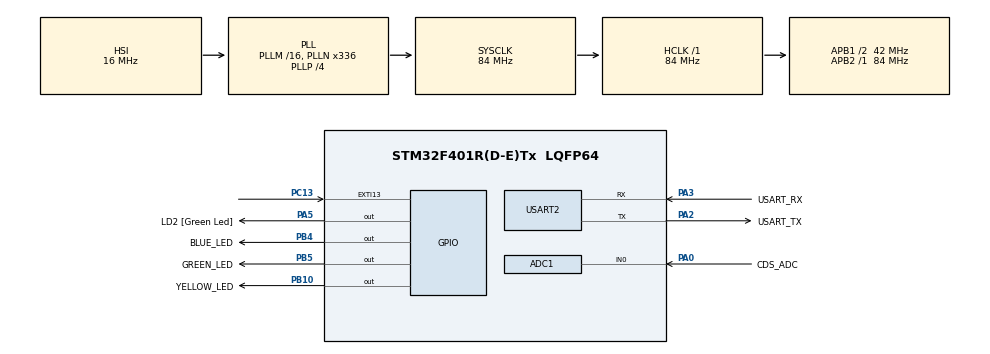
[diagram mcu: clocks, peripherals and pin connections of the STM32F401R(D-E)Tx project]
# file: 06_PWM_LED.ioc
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ADC1.Channel-0\#ChannelRegularConversion=ADC_CHANNEL_0
ADC1.ClockPrescaler=ADC_CLOCK_SYNC_PCLK_DIV4
ADC1.NbrOfConversionFlag=1
ADC1.Rank-0\#ChannelRegularConversion=1
ADC1.SamplingTime-0\#ChannelRegularConversion=ADC_SAMPLETIME_84CYCLES
Dma.Request0=USART2_RX
Dma.Request1=USART2_TX
Dma.USART2_RX.0.Channel=DMA_CHANNEL_4
Dma.USART2_RX.0.Direction=DMA_PERIPH_TO_MEMORY
Dma.USART2_RX.0.FIFOMode=DMA_FIFOMODE_DISABLE
Dma.USART2_RX.0.Instance=DMA1_Stream5
Dma.USART2_RX.0.MemDataAlignment=DMA_MDATAALIGN_BYTE
Dma.USART2_RX.0.MemInc=DMA_MINC_ENABLE
Dma.USART2_RX.0.Mode=DMA_NORMAL
Dma.USART2_RX.0.PeriphDataAlignment=DMA_PDATAALIGN_BYTE
Dma.USART2_RX.0.PeriphInc=DMA_PINC_DISABLE
Dma.USART2_RX.0.Priority=DMA_PRIORITY_LOW
Dma.USART2_TX.1.Channel=DMA_CHANNEL_4
Dma.USART2_TX.1.Direction=DMA_MEMORY_TO_PERIPH
Dma.USART2_TX.1.FIFOMode=DMA_FIFOMODE_DISABLE
Dma.USART2_TX.1.Instance=DMA1_Stream6
Dma.USART2_TX.1.MemDataAlignment=DMA_MDATAALIGN_BYTE
Dma.USART2_TX.1.MemInc=DMA_MINC_ENABLE
Dma.USART2_TX.1.Mode=DMA_NORMAL
Dma.USART2_TX.1.PeriphDataAlignment=DMA_PDATAALIGN_BYTE
Dma.USART2_TX.1.PeriphInc=DMA_PINC_DISABLE
Dma.USART2_TX.1.Priority=DMA_PRIORITY_LOW
Mcu.Family=STM32F4
Mcu.Name=STM32F401R(D-E)Tx
Mcu.Package=LQFP64
NVIC.DMA1_Stream5_IRQn=true\:0\:0\:false\:false\:true\:false\:true\:true
NVIC.DMA1_Stream6_IRQn=true\:0\:0\:false\:false\:true\:false\:true\:true
NVIC.PriorityGroup=NVIC_PRIORITYGROUP_4
NVIC.TIM2_IRQn=true\:0\:0\:false\:false\:true\:true\:true\:true
NVIC.USART2_IRQn=true\:0\:0\:false\:false\:true\:true\:true\:true
PA0-WKUP.GPIO_Label=CDS_ADC
PA0-WKUP.Mode=IN0
PA0-WKUP.Signal=ADC1_IN0
PA13.GPIO_Label=TMS
PA13.Mode=Trace_Asynchronous_SW
PA13.Signal=SYS_JTMS-SWDIO
PA14.GPIO_Label=TCK
PA14.Mode=Trace_Asynchronous_SW
PA14.Signal=SYS_JTCK-SWCLK
PA2.GPIO_Label=USART_TX
PA2.GPIO_Mode=GPIO_MODE_AF_PP
PA2.GPIO_PuPd=GPIO_NOPULL
PA2.GPIO_Speed=GPIO_SPEED_FREQ_LOW
PA2.Mode=Asynchronous
PA2.Signal=USART2_TX
PA3.GPIO_Label=USART_RX
PA3.GPIO_Mode=GPIO_MODE_AF_PP
PA3.GPIO_PuPd=GPIO_NOPULL
PA3.GPIO_Speed=GPIO_SPEED_FREQ_LOW
PA3.Mode=Asynchronous
PA3.Signal=USART2_RX
PA5.GPIO_Label=LD2 [Green Led]
PA5.GPIO_Mode=GPIO_MODE_OUTPUT_PP
PA5.GPIO_PuPd=GPIO_NOPULL
PA5.GPIO_Speed=GPIO_SPEED_FREQ_LOW
PA5.Signal=GPIO_Output
PA8.GPIO_Alternate=GPIO_AF1_TIM1
PA8.GPIO_Label=PWM_RED_LED
PA8.GPIO_Mode=GPIO_MODE_AF_PP
PA8.GPIO_PuPd=GPIO_NOPULL
PA8.GPIO_Speed=GPIO_SPEED_FREQ_LOW
PA8.Signal=S_TIM1_CH1
PB10.GPIO_Label=YELLOW_LED
PB10.Signal=GPIO_Output
PB3.GPIO_Label=SWO
PB3.Mode=Trace_Asynchronous_SW
PB3.Signal=SYS_JTDO-SWO
PB4.GPIO_Label=BLUE_LED
PB4.Signal=GPIO_Output
PB5.GPIO_Label=GREEN_LED
PB5.Signal=GPIO_Output
PC13-ANTI_TAMP.Signal=GPXTI13
PC14-OSC32_IN.Mode=LSE-External-Oscillator
PC14-OSC32_IN.Signal=RCC_OSC32_IN
PC15-OSC32_OUT.Mode=LSE-External-Oscillator
PC15-OSC32_OUT.Signal=RCC_OSC32_OUT
PH0\ -\ OSC_IN.Mode=HSE-External-Clock-Source
PH0\ -\ OSC_IN.Signal=RCC_OSC_IN
PH1\ -\ OSC_OUT.Mode=HSE-External-Clock-Source
PH1\ -\ OSC_OUT.Signal=RCC_OSC_OUT
ProjectManager.HeapSize=0x200
ProjectManager.StackSize=0x400
ProjectManager.TargetToolchain=CMake
RCC.48MHZClocksFreq_Value=48000000
RCC.AHBFreq_Value=84000000
RCC.APB1CLKDivider=RCC_HCLK_DIV2
RCC.APB1Freq_Value=42000000
RCC.APB1TimFreq_Value=84000000
RCC.APB2Freq_Value=84000000
RCC.APB2TimFreq_Value=84000000
RCC.CortexFreq_Value=84000000
RCC.HCLKFreq_Value=84000000
RCC.HSE_VALUE=8000000
RCC.HSI_VALUE=16000000
RCC.PLLN=336
RCC.PLLP=RCC_PLLP_DIV4
RCC.PLLQ=7
RCC.SYSCLKFreq_VALUE=84000000
RCC.SYSCLKSource=RCC_SYSCLKSOURCE_PLLCLK
RCC.VCOOutputFreq_Value=336000000
USART2.DMAParams=USART2_RX,USART2_TX
USART2.VirtualMode=VM_ASYNC
TIM1.Channel-PWM\ Generation1=TIM_CHANNEL_1
TIM1.Period=999
TIM1.Prescaler=83
TIM1.Pulse-PWM\ Generation1=0
TIM2.Period=4999
TIM2.Prescaler=8399
board=NUCLEO-F401RE

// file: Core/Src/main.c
/* USER CODE BEGIN Header */
/**
  ******************************************************************************
  * @file           : main.c
  * @brief          : Main program body
  ******************************************************************************
  * @attention
  *
  * Copyright (c) 2026 STMicroelectronics.
  * All rights reserved.
  *
  * This software is licensed under terms that can be found in the LICENSE file
  * in the root directory of this software component.
  * If no LICENSE file comes with this software, it is provided AS-IS.
  *
  ******************************************************************************
  */
/* USER CODE END Header */
#include "main.h"

/* USER CODE BEGIN Includes */

#include <stdio.h>
#include <string.h>

/* USER CODE END Includes */

/* USER CODE BEGIN PTD */

typedef enum
{
  LED_STATE_IDLE,
  LED_STATE_RUNNING,
  LED_STATE_WARNING,
  LED_STATE_ERROR,
  LED_STATE_COUNT
} LED_State;

/* USER CODE END PTD */

/* USER CODE BEGIN PD */

#define BUTTON_DEBOUNCE_MS 50U
#define UART_RX_BUFFER_SIZE 32U
#define PWM_PERIOD 999U
#define UART_TX_BUFFER_SIZE 128U
#define CDS_BRIGHT_THRESHOLD 1200U
#define CDS_NORMAL_THRESHOLD 2100U
#define CDS_DIM_THRESHOLD 3000U

/* USER CODE END PD */

ADC_HandleTypeDef hadc1;
TIM_HandleTypeDef htim1;
TIM_HandleTypeDef htim2;

/* USART2 설정과 상태를 HAL 드라이버에 전달하는 핸들 */
UART_HandleTypeDef huart2;
DMA_HandleTypeDef hdma_usart2_rx;
DMA_HandleTypeDef hdma_usart2_tx;

/* USER CODE BEGIN PV */

static LED_State currentState = LED_STATE_IDLE;
static uint8_t uartDmaRxBuffer[UART_RX_BUFFER_SIZE];
static char uartRxBuffer[UART_RX_BUFFER_SIZE];
static volatile uint8_t uartRxIndex = 0U;
static volatile uint8_t uartCommandReady = 0U;
static volatile uint8_t uartRxOverflow = 0U;
static uint8_t uartDmaTxBuffer[UART_TX_BUFFER_SIZE];
static volatile uint8_t uartDmaTxComplete = 1U;
static volatile uint8_t timerSampleRequested = 0U;

/* USER CODE END PV */

void SystemClock_Config(void);
void HAL_TIM_MspPostInit(TIM_HandleTypeDef *htim);
static void MX_ADC1_Init(void);
static void MX_TIM1_Init(void);
static void MX_TIM2_Init(void);
static void MX_GPIO_Init(void);
static void MX_DMA_Init(void);
static void MX_USART2_UART_Init(void);
/* USER CODE BEGIN PFP */

static void LED_AllOff(void);
static void LED_On(GPIO_TypeDef *GPIOx, uint16_t GPIO_Pin);
static void LED_ShowState(LED_State state);
static void UART_PrintState(LED_State state);
static void UART_HandleCommand(const char *command);
static void UART_StartDmaReceive(void);
static void UART_StoreReceivedData(const uint8_t *data, uint16_t size);
static HAL_StatusTypeDef ADC_ReadCdS(uint32_t *rawValue);
static void CdS_ProcessSample(void);
static void PWM_SetDutyFromCdS(uint32_t rawValue);
static LED_State CdS_GetBrightnessState(uint32_t rawValue);
static const char *CdS_GetBrightnessName(LED_State state);

/* USER CODE END PFP */

/* USER CODE BEGIN 0 */

int _write(int file, char *ptr, int len)
{
  int sent = 0;

  (void)file;

  while (sent < len)
  {
    uint16_t chunkSize = (uint16_t)(len - sent);

    if (chunkSize > UART_TX_BUFFER_SIZE)
    {
      chunkSize = UART_TX_BUFFER_SIZE;
    }

    memcpy(uartDmaTxBuffer, &ptr[sent], chunkSize);
    uartDmaTxComplete = 0U;

    if (HAL_UART_Transmit_DMA(&huart2, uartDmaTxBuffer, chunkSize) != HAL_OK)
    {
      return -1;
    }

    while (uartDmaTxComplete == 0U)
    {
      __WFI();
    }

    sent += chunkSize;
  }

  return len;
}

/* USER CODE END 0 */

int main(void)
{

  /* USER CODE BEGIN 1 */

  GPIO_PinState lastButtonReading = GPIO_PIN_RESET;
  GPIO_PinState stableButtonState = GPIO_PIN_RESET;
  uint32_t lastDebounceTime = 0U;

  /* USER CODE END 1 */

  /* MCU Configuration--------------------------------------------------------*/

  /* HAL 라이브러리, Flash 인터페이스, 1 ms 주기의 SysTick 타이머를 초기화한다. */
  HAL_Init();

  /* 내부 HSI 오실레이터와 PLL을 이용해 시스템 클럭을 84 MHz로 설정한다. */
  SystemClock_Config();

  MX_ADC1_Init();
  MX_TIM1_Init();
  MX_TIM2_Init();

  /* LED와 사용자 버튼이 연결된 GPIO를 초기화한다. */
  MX_GPIO_Init();

  MX_DMA_Init();

  /* ST-LINK 가상 COM 포트에 연결된 USART2를 115200 bps로 초기화한다. */
  MX_USART2_UART_Init();
  /* USER CODE BEGIN 2 */

  LED_ShowState(currentState);

  printf("Hello STM32!\r\n");
  UART_PrintState(currentState);

  UART_StartDmaReceive();

  if (HAL_TIM_PWM_Start(&htim1, TIM_CHANNEL_1) != HAL_OK)
  {
    Error_Handler();
  }

  if (HAL_TIM_Base_Start_IT(&htim2) != HAL_OK)
  {
    Error_Handler();
  }

  /* USER CODE END 2 */

  /* 초기화가 끝난 뒤 프로그램이 계속 실행되는 메인 반복 구간 */
  /* USER CODE BEGIN WHILE */
  while (1)
  {
    if (timerSampleRequested != 0U)
    {
      timerSampleRequested = 0U;
      CdS_ProcessSample();
    }

    GPIO_PinState buttonReading = HAL_GPIO_ReadPin(USER_BUTTON_GPIO_Port, USER_BUTTON_Pin);

    if (buttonReading != lastButtonReading)
    {
      lastDebounceTime = HAL_GetTick();
    }

    if ((HAL_GetTick() - lastDebounceTime) >= BUTTON_DEBOUNCE_MS)
    {
      if (buttonReading != stableButtonState)
      {
        stableButtonState = buttonReading;

        if (stableButtonState == GPIO_PIN_SET)
        {
          currentState = (LED_State)((currentState + 1) % LED_STATE_COUNT);
          LED_ShowState(currentState);
          UART_PrintState(currentState);
        }
      }
    }

    lastButtonReading = buttonReading;

    if (uartCommandReady != 0U)
    {
      if (uartRxOverflow != 0U)
      {
        printf("Command too long\r\n");
      }
      else
      {
        UART_HandleCommand(uartRxBuffer);
      }

      uartRxIndex = 0U;
      uartRxOverflow = 0U;
      uartCommandReady = 0U;
    }
    /* USER CODE END WHILE */

  }
}

void SystemClock_Config(void)
{
  /* 오실레이터와 버스 클럭 설정 구조체를 0으로 초기화한다. */
  RCC_OscInitTypeDef RCC_OscInitStruct = {0};
  RCC_ClkInitTypeDef RCC_ClkInitStruct = {0};

  /** 전원 제어 장치의 클럭을 활성화하고 84 MHz 동작에 맞는 전압 스케일을 선택한다.
  */
  __HAL_RCC_PWR_CLK_ENABLE();
  __HAL_PWR_VOLTAGESCALING_CONFIG(PWR_REGULATOR_VOLTAGE_SCALE2);

  /** 16 MHz 내부 HSI를 PLL 입력으로 사용해 84 MHz 시스템 클럭을 만든다.
  * in the RCC_OscInitTypeDef structure.
  */
  RCC_OscInitStruct.OscillatorType = RCC_OSCILLATORTYPE_HSI;
  RCC_OscInitStruct.HSIState = RCC_HSI_ON;
  RCC_OscInitStruct.HSICalibrationValue = RCC_HSICALIBRATION_DEFAULT;
  RCC_OscInitStruct.PLL.PLLState = RCC_PLL_ON;
  RCC_OscInitStruct.PLL.PLLSource = RCC_PLLSOURCE_HSI;
  RCC_OscInitStruct.PLL.PLLM = 16;
  RCC_OscInitStruct.PLL.PLLN = 336;
  RCC_OscInitStruct.PLL.PLLP = RCC_PLLP_DIV4;
  RCC_OscInitStruct.PLL.PLLQ = 7;
  /* 오실레이터 설정에 실패하면 안전하게 오류 처리 루틴으로 이동한다. */
  if (HAL_RCC_OscConfig(&RCC_OscInitStruct) != HAL_OK)
  {
    Error_Handler();
  }

  /** SYSCLK와 AHB는 84 MHz, APB1은 42 MHz, APB2는 84 MHz로 설정한다.
  */
  RCC_ClkInitStruct.ClockType = RCC_CLOCKTYPE_HCLK|RCC_CLOCKTYPE_SYSCLK
                              |RCC_CLOCKTYPE_PCLK1|RCC_CLOCKTYPE_PCLK2;
  RCC_ClkInitStruct.SYSCLKSource = RCC_SYSCLKSOURCE_PLLCLK;
  RCC_ClkInitStruct.AHBCLKDivider = RCC_SYSCLK_DIV1;
  RCC_ClkInitStruct.APB1CLKDivider = RCC_HCLK_DIV2;
  RCC_ClkInitStruct.APB2CLKDivider = RCC_HCLK_DIV1;

  if (HAL_RCC_ClockConfig(&RCC_ClkInitStruct, FLASH_LATENCY_2) != HAL_OK)
  {
    Error_Handler();
  }
}

static void MX_ADC1_Init(void)
{
  ADC_ChannelConfTypeDef channelConfig = {0};

  hadc1.Instance = ADC1;
  hadc1.Init.ClockPrescaler = ADC_CLOCK_SYNC_PCLK_DIV4;
  hadc1.Init.Resolution = ADC_RESOLUTION_12B;
  hadc1.Init.ScanConvMode = DISABLE;
  hadc1.Init.ContinuousConvMode = DISABLE;
  hadc1.Init.DiscontinuousConvMode = DISABLE;
  hadc1.Init.ExternalTrigConvEdge = ADC_EXTERNALTRIGCONVEDGE_NONE;
  hadc1.Init.ExternalTrigConv = ADC_SOFTWARE_START;
  hadc1.Init.DataAlign = ADC_DATAALIGN_RIGHT;
  hadc1.Init.NbrOfConversion = 1;
  hadc1.Init.DMAContinuousRequests = DISABLE;
  hadc1.Init.EOCSelection = ADC_EOC_SINGLE_CONV;

  if (HAL_ADC_Init(&hadc1) != HAL_OK)
  {
    Error_Handler();
  }

  channelConfig.Channel = ADC_CHANNEL_0;
  channelConfig.Rank = 1;
  channelConfig.SamplingTime = ADC_SAMPLETIME_84CYCLES;

  if (HAL_ADC_ConfigChannel(&hadc1, &channelConfig) != HAL_OK)
  {
    Error_Handler();
  }
}

static void MX_TIM2_Init(void)
{
  htim2.Instance = TIM2;
  htim2.Init.Prescaler = 8399;
  htim2.Init.CounterMode = TIM_COUNTERMODE_UP;
  htim2.Init.Period = 4999;
  htim2.Init.ClockDivision = TIM_CLOCKDIVISION_DIV1;
  htim2.Init.AutoReloadPreload = TIM_AUTORELOAD_PRELOAD_DISABLE;

  if (HAL_TIM_Base_Init(&htim2) != HAL_OK)
  {
    Error_Handler();
  }
}

static void MX_TIM1_Init(void)
{
  TIM_OC_InitTypeDef channelConfig = {0};

  htim1.Instance = TIM1;
  htim1.Init.Prescaler = 83;
  htim1.Init.CounterMode = TIM_COUNTERMODE_UP;
  htim1.Init.Period = PWM_PERIOD;
  htim1.Init.ClockDivision = TIM_CLOCKDIVISION_DIV1;
  htim1.Init.RepetitionCounter = 0;
  htim1.Init.AutoReloadPreload = TIM_AUTORELOAD_PRELOAD_DISABLE;

  if (HAL_TIM_PWM_Init(&htim1) != HAL_OK)
  {
    Error_Handler();
  }

  channelConfig.OCMode = TIM_OCMODE_PWM1;
  channelConfig.Pulse = 0;
  channelConfig.OCPolarity = TIM_OCPOLARITY_HIGH;
  channelConfig.OCFastMode = TIM_OCFAST_DISABLE;

  if (HAL_TIM_PWM_ConfigChannel(&htim1, &channelConfig, TIM_CHANNEL_1) != HAL_OK)
  {
    Error_Handler();
  }

  HAL_TIM_MspPostInit(&htim1);
}

static void MX_DMA_Init(void)
{
  __HAL_RCC_DMA1_CLK_ENABLE();

  HAL_NVIC_SetPriority(DMA1_Stream5_IRQn, 0, 0);
  HAL_NVIC_EnableIRQ(DMA1_Stream5_IRQn);

  HAL_NVIC_SetPriority(DMA1_Stream6_IRQn, 0, 0);
  HAL_NVIC_EnableIRQ(DMA1_Stream6_IRQn);
}

static void MX_USART2_UART_Init(void)
{

  /* USART2: 115200 bps, 데이터 8비트, 패리티 없음, 정지 비트 1개(8-N-1) */
  huart2.Instance = USART2;
  huart2.Init.BaudRate = 115200;
  huart2.Init.WordLength = UART_WORDLENGTH_8B;
  huart2.Init.StopBits = UART_STOPBITS_1;
  huart2.Init.Parity = UART_PARITY_NONE;
  huart2.Init.Mode = UART_MODE_TX_RX;
  huart2.Init.HwFlowCtl = UART_HWCONTROL_NONE;
  huart2.Init.OverSampling = UART_OVERSAMPLING_16;
  if (HAL_UART_Init(&huart2) != HAL_OK)
  {
    Error_Handler();
  }

}

static void MX_GPIO_Init(void)
{
  /* 한 개 이상의 GPIO 핀에 공통으로 적용할 설정 구조체 */
  GPIO_InitTypeDef GPIO_InitStruct = {0};

  /* GPIO 레지스터에 접근할 수 있도록 사용하는 포트의 클럭을 활성화한다. */
  __HAL_RCC_GPIOC_CLK_ENABLE();
  __HAL_RCC_GPIOH_CLK_ENABLE();
  __HAL_RCC_GPIOA_CLK_ENABLE();
  __HAL_RCC_GPIOB_CLK_ENABLE();

  /* 초기화 중 LED가 의도치 않게 켜지지 않도록 모든 LED 출력을 LOW로 만든다. */
  HAL_GPIO_WritePin(GPIOA, LD2_Pin, GPIO_PIN_RESET);

  /*Configure GPIO pin Output Level */
  HAL_GPIO_WritePin(GPIOB, YELLOW_LED_Pin|BLUE_LED_Pin|GREEN_LED_Pin, GPIO_PIN_RESET);

  /* PC13 사용자 버튼을 폴링 입력으로 사용한다. */
  GPIO_InitStruct.Pin = USER_BUTTON_Pin;
  GPIO_InitStruct.Mode = GPIO_MODE_INPUT;
  GPIO_InitStruct.Pull = GPIO_NOPULL;
  HAL_GPIO_Init(USER_BUTTON_GPIO_Port, &GPIO_InitStruct);

  /* PA5(LD2): 푸시풀 출력, 내부 풀업/풀다운 없음 */
  GPIO_InitStruct.Pin = LD2_Pin;
  GPIO_InitStruct.Mode = GPIO_MODE_OUTPUT_PP;
  GPIO_InitStruct.Pull = GPIO_NOPULL;
  GPIO_InitStruct.Speed = GPIO_SPEED_FREQ_LOW;
  HAL_GPIO_Init(GPIOA, &GPIO_InitStruct);

  /* PB10(노랑), PB4(파랑), PB5(초록 LED): 푸시풀 출력 */
  GPIO_InitStruct.Pin = YELLOW_LED_Pin|BLUE_LED_Pin|GREEN_LED_Pin;
  GPIO_InitStruct.Mode = GPIO_MODE_OUTPUT_PP;
  GPIO_InitStruct.Pull = GPIO_NOPULL;
  GPIO_InitStruct.Speed = GPIO_SPEED_FREQ_LOW;
  HAL_GPIO_Init(GPIOB, &GPIO_InitStruct);

}

/* USER CODE BEGIN 4 */

static HAL_StatusTypeDef ADC_ReadCdS(uint32_t *rawValue)
{
  HAL_StatusTypeDef status;

  status = HAL_ADC_Start(&hadc1);
  if (status != HAL_OK)
  {
    return status;
  }

  status = HAL_ADC_PollForConversion(&hadc1, 10U);
  if (status == HAL_OK)
  {
    *rawValue = HAL_ADC_GetValue(&hadc1);
  }

  if (HAL_ADC_Stop(&hadc1) != HAL_OK && status == HAL_OK)
  {
    status = HAL_ERROR;
  }

  return status;
}

static void CdS_ProcessSample(void)
{
  uint32_t rawValue;

  if (ADC_ReadCdS(&rawValue) == HAL_OK)
  {
    uint32_t millivolts = (rawValue * 3300U) / 4095U;

    currentState = CdS_GetBrightnessState(rawValue);
    LED_ShowState(currentState);
    PWM_SetDutyFromCdS(rawValue);

    printf("CdS raw=%lu, voltage=%lu mV, brightness=%s, pwm=%lu/1000\r\n",
           (unsigned long)rawValue, (unsigned long)millivolts,
           CdS_GetBrightnessName(currentState),
           (unsigned long)((rawValue * (PWM_PERIOD + 1U)) / 4095U));
  }
  else
  {
    printf("CdS ADC read error\r\n");
  }
}

static void PWM_SetDutyFromCdS(uint32_t rawValue)
{
  uint32_t pulse = (rawValue * (PWM_PERIOD + 1U)) / 4095U;

  __HAL_TIM_SET_COMPARE(&htim1, TIM_CHANNEL_1, pulse);
}

void HAL_TIM_PeriodElapsedCallback(TIM_HandleTypeDef *htim)
{
  if (htim->Instance == TIM2)
  {
    timerSampleRequested = 1U;
  }
}

static LED_State CdS_GetBrightnessState(uint32_t rawValue)
{
  if (rawValue <= CDS_BRIGHT_THRESHOLD)
  {
    return LED_STATE_IDLE;
  }

  if (rawValue <= CDS_NORMAL_THRESHOLD)
  {
    return LED_STATE_RUNNING;
  }

  if (rawValue <= CDS_DIM_THRESHOLD)
  {
    return LED_STATE_WARNING;
  }

  return LED_STATE_ERROR;
}

static const char *CdS_GetBrightnessName(LED_State state)
{
  switch (state)
  {
    case LED_STATE_IDLE:
      return "BRIGHT";

    case LED_STATE_RUNNING:
      return "NORMAL";

    case LED_STATE_WARNING:
      return "DIM";

    case LED_STATE_ERROR:
      return "DARK";

    default:
      return "UNKNOWN";
  }
}

static void LED_AllOff(void)
{
  HAL_GPIO_WritePin(GPIOA, RED_LED_Pin, GPIO_PIN_RESET);
  HAL_GPIO_WritePin(GPIOB, YELLOW_LED_Pin|BLUE_LED_Pin|GREEN_LED_Pin, GPIO_PIN_RESET);
}

static void LED_On(GPIO_TypeDef *GPIOx, uint16_t GPIO_Pin)
{
  LED_AllOff();
  HAL_GPIO_WritePin(GPIOx, GPIO_Pin, GPIO_PIN_SET);
}

static void LED_ShowState(LED_State state)
{
  switch (state)
  {
    case LED_STATE_IDLE:
      LED_On(GREEN_LED_GPIO_Port, GREEN_LED_Pin);
      break;

    case LED_STATE_RUNNING:
      LED_On(BLUE_LED_GPIO_Port, BLUE_LED_Pin);
      break;

    case LED_STATE_WARNING:
      LED_On(YELLOW_LED_GPIO_Port, YELLOW_LED_Pin);
      break;

    case LED_STATE_ERROR:
      LED_On(RED_LED_GPIO_Port, RED_LED_Pin);
      break;

    default:
      LED_AllOff();
      break;
  }
}

static void UART_PrintState(LED_State state)
{
  const char *stateName;

  switch (state)
  {
    case LED_STATE_IDLE:
      stateName = "IDLE";
      break;

    case LED_STATE_RUNNING:
      stateName = "RUNNING";
      break;

    case LED_STATE_WARNING:
      stateName = "WARNING";
      break;

    case LED_STATE_ERROR:
      stateName = "ERROR";
      break;

    default:
      stateName = "UNKNOWN";
      break;
  }

  printf("State: %s\r\n", stateName);
}

static void UART_HandleCommand(const char *command)
{
  printf("Command: %s\r\n", command);

  if ((strcmp(command, "g") == 0) || (strcmp(command, "G") == 0)
      || (strcmp(command, "led green") == 0))
  {
    currentState = LED_STATE_IDLE;
  }
  else if ((strcmp(command, "b") == 0) || (strcmp(command, "B") == 0)
           || (strcmp(command, "led blue") == 0))
  {
    currentState = LED_STATE_RUNNING;
  }
  else if ((strcmp(command, "y") == 0) || (strcmp(command, "Y") == 0)
           || (strcmp(command, "led yellow") == 0))
  {
    currentState = LED_STATE_WARNING;
  }
  else if ((strcmp(command, "r") == 0) || (strcmp(command, "R") == 0)
           || (strcmp(command, "led red") == 0))
  {
    currentState = LED_STATE_ERROR;
  }
  else if (strcmp(command, "status") == 0)
  {
    UART_PrintState(currentState);
    return;
  }
  else if (strcmp(command, "help") == 0)
  {
    printf("Commands: led green, led blue, led yellow, led red, status, help\r\n");
    return;
  }
  else
  {
    printf("Unknown command. Type help.\r\n");
    return;
  }

  LED_ShowState(currentState);
  UART_PrintState(currentState);
}

static void UART_StartDmaReceive(void)
{
  if (HAL_UARTEx_ReceiveToIdle_DMA(&huart2, uartDmaRxBuffer,
                                   UART_RX_BUFFER_SIZE) != HAL_OK)
  {
    Error_Handler();
  }

  __HAL_DMA_DISABLE_IT(&hdma_usart2_rx, DMA_IT_HT);
}

static void UART_StoreReceivedData(const uint8_t *data, uint16_t size)
{
  for (uint16_t i = 0U; (i < size) && (uartCommandReady == 0U); i++)
  {
    uint8_t receivedByte = data[i];

    if ((receivedByte == '\r') || (receivedByte == '\n'))
    {
      if (uartRxIndex > 0U)
      {
        uartRxBuffer[uartRxIndex] = '\0';
        uartCommandReady = 1U;
      }
    }
    else if ((receivedByte == '\b') || (receivedByte == 0x7FU))
    {
      if (uartRxIndex > 0U)
      {
        uartRxIndex--;
      }
    }
    else if (uartRxIndex < (UART_RX_BUFFER_SIZE - 1U))
    {
      uartRxBuffer[uartRxIndex] = (char)receivedByte;
      uartRxIndex++;
    }
    else
    {
      uartRxOverflow = 1U;
      uartCommandReady = 1U;
    }
  }
}

void HAL_UARTEx_RxEventCallback(UART_HandleTypeDef *huart, uint16_t size)
{
  if (huart->Instance == USART2)
  {
    UART_StoreReceivedData(uartDmaRxBuffer, size);
    UART_StartDmaReceive();
  }
}

void HAL_UART_TxCpltCallback(UART_HandleTypeDef *huart)
{
  if (huart->Instance == USART2)
  {
    uartDmaTxComplete = 1U;
  }
}

/* USER CODE END 4 */

void Error_Handler(void)
{
  /* USER CODE BEGIN Error_Handler_Debug */
  /* 치명적인 초기화 오류가 발생하면 인터럽트를 막고 이 위치에서 정지한다. */
  __disable_irq();
  while (1)
  {
  }
  /* USER CODE END Error_Handler_Debug */
}
